# M061 register map
File version: 2.0.2.1
CPU: 
Registers are 32-bit, read-write, reset 0x0 unless marked. A register's access mark holds for its fields unless they carry their own. Offsets are from the block's base; [hi:lo] are bit positions; {n}, {i} and the like mark numbered series.

## TB0 — 16-bit Timer_Event Counter (TB)
Base 0x400C4000
Same registers: TB1 0x440C4100
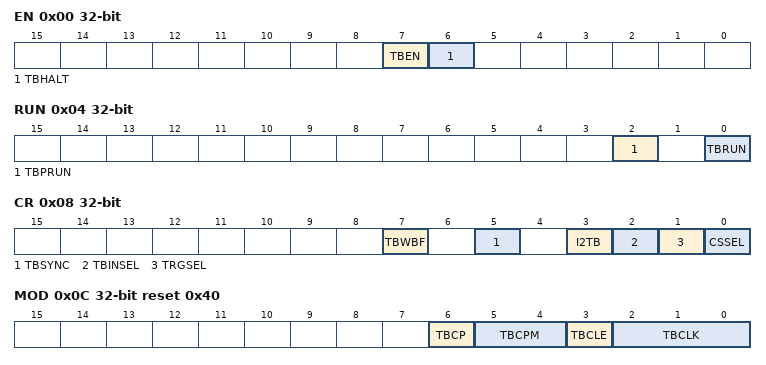
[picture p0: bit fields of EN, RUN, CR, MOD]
0x00 EN — TB Enable Register
  [7] TBEN, [6] TBHALT
0x04 RUN — TB RUN Register
  [2] TBPRUN, [0] TBRUN
0x08 CR — TB Control Register
  [7] TBWBF, [5] TBSYNC, [3] I2TB, [2] TBINSEL, [1] TRGSEL, [0] CSSEL
0x0C MOD reset 0x40 — TB Mode Register
  [6] TBCP wo, [5:4] TBCPM, [3] TBCLE, [2:0] TBCLK
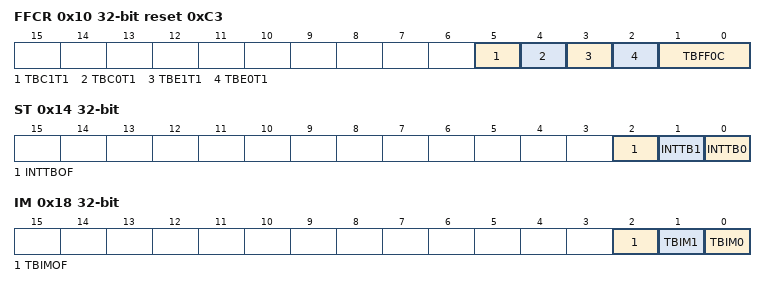
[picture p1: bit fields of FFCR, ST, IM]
0x10 FFCR reset 0xC3 — TB Flip-Flop Control Register
  [5] TBC1T1, [4] TBC0T1, [3] TBE1T1, [2] TBE0T1, [1:0] TBFF0C
0x14 ST ro — TB Status Register
  [2] INTTBOF, [1] INTTB1, [0] INTTB0
0x18 IM — TB Interrupt Mask Register
  [2] TBIMOF, [1] TBIM1, [0] TBIM0
0x1C UC ro — TB Read Capture Register
  [15:0] UC
0x20 RG0 — TB RG0 Timer Register
  [15:0] TBRG0
0x24 RG1 — TB RG1 Timer Register
  [15:0] TBRG1
0x28 CP0 ro (reset mask 0xFFFF0000) — TB CP0 Capture Register
  [15:0] TBCP0
0x2C CP1 ro (reset mask 0xFFFF0000) — TB CP1 Capture Register
  [15:0] TBCP1

## T16A0 — 16-bit TimerA
Base 0x4008D000
Same registers: T16A1 0x4008E000, T16A2 0x4008F000, T16A3 0x40090000, T16A4 0x40091000, T16A5 0x44092000, T16A6 0x44093000
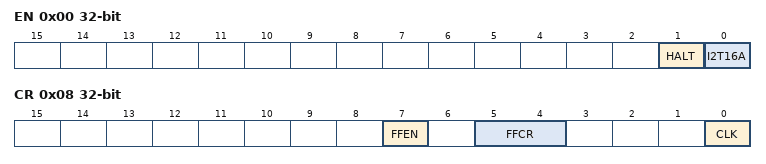
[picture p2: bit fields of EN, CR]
0x00 EN — Enable Register
  [1] HALT, [0] I2T16A
0x04 RUN
  [0] RUN
0x08 CR — Control Register
  [7] FFEN, [5:4] FFCR, [0] CLK
0x0C RG — Timer Register
  [15:0] RG
0x10 CP ro — Capture Register
  [15:0] CP

## WD0 — Watchdog Timer (WD)
Base 0x400F2000
Same registers: WD1 0x440F2100
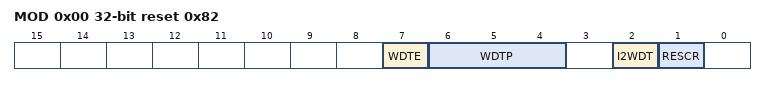
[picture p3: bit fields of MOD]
0x00 MOD reset 0x82 — WD Mode Register
  [7] WDTE, [6:4] WDTP, [2] I2WDT, [1] RESCR
0x04 CR wo (reset mask 0xFFFFFF00) — WD Control Register
  [7:0] WDCR

## SC0 — Serial Channel (SC)
Base 0x400E1000
Same registers: SC1 0x400E1100, SC2 0x400E1200, SC3 0x400E1300
0x00 EN — SC Enable Register
  [0] SIOE
0x04 BUF — SC Buffer Register
  [7:0] TB_RB
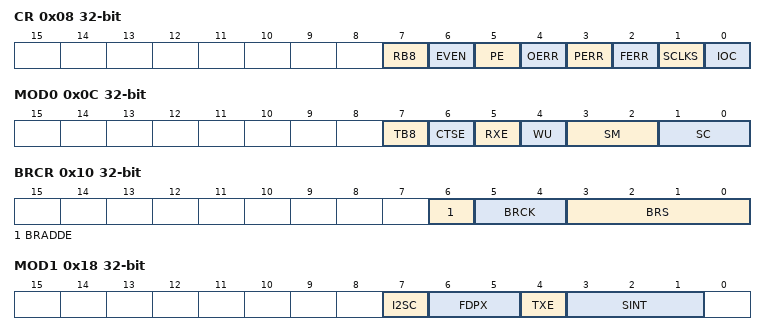
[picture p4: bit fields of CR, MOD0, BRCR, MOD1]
0x08 CR — SC Control Register
  [7] RB8 ro, [6] EVEN, [5] PE, [4] OERR ro, [3] PERR ro, [2] FERR ro, [1] SCLKS, [0] IOC
0x0C MOD0 — SC Mode Control Register 0
  [7] TB8, [6] CTSE, [5] RXE, [4] WU, [3:2] SM, [1:0] SC
0x10 BRCR — SC Baud Rate Generator Control Register
  [6] BRADDE, [5:4] BRCK, [3:0] BRS
0x14 BRADD — SC Baud Rate Generator Control Register 2
  [3:0] BRK
0x18 MOD1 — SC Mode Control Register 1
  [7] I2SC, [6:5] FDPX, [4] TXE, [3:1] SINT
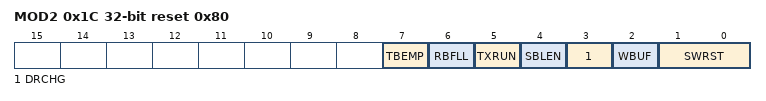
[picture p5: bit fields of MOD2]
0x1C MOD2 reset 0x80 — SC Mode Control Register 2
  [7] TBEMP ro, [6] RBFLL ro, [5] TXRUN ro, [4] SBLEN, [3] DRCHG, [2] WBUF, [1:0] SWRST

## SBI — Serial Bus Interface (SBI)
Base 0x400E0000
0x00 CR0 — SBI Control Register 0
  [7] SBIEN
0x04 CR1_A reset 0x3 — SBI Control Register 1 (I2C Mode)
  [7:5] BC, [4] ACK, [0] SWRMON ro, [2:0] SCK wo
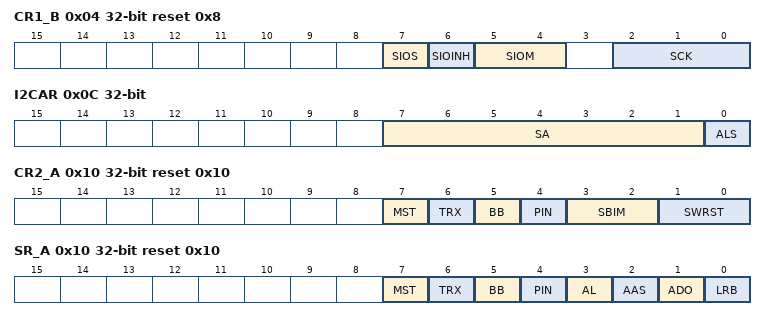
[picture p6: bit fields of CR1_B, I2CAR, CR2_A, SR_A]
0x04 CR1_B reset 0x8 (SBI_CR1 view) — SBI Control Register 1 (SIO Mode)
  [7] SIOS, [6] SIOINH, [5:4] SIOM, [2:0] SCK
0x08 DBR — SBI Data Buffer Register
  [7:0] DB
0x0C I2CAR — SBI I2C Bus Address Register
  [7:1] SA, [0] ALS
0x10 CR2_A wo reset 0x10 — SBI Control Register 2 (I2C Mode)
  [7] MST, [6] TRX, [5] BB, [4] PIN, [3:2] SBIM, [1:0] SWRST
0x10 CR2_B wo reset 0xF3 (SBI_CR2 view) — SBI Control Register 2 (SIO Mode)
  [3:2] SBIM
0x10 SR_A ro reset 0x10 — SBI Status Register (I2C Mode)
  [7] MST, [6] TRX, [5] BB, [4] PIN, [3] AL, [2] AAS, [1] ADO, [0] LRB
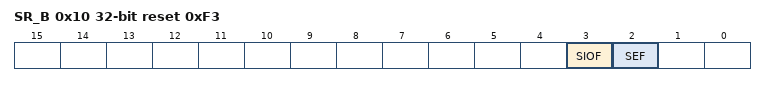
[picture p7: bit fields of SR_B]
0x10 SR_B ro reset 0xF3 (SBI_SR view) — SBI Status Register (SIO Mode)
  [3] SIOF, [2] SEF
0x14 BR0 reset 0xBE — SBI Baud Rate Register 0
  [6] I2SBI

## AD — Analog-to-Digital Converter (AD)
Base 0x400FC000
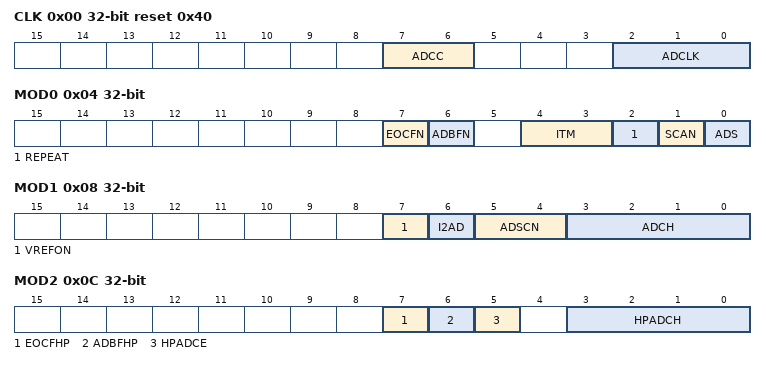
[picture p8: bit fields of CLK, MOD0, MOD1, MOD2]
0x00 CLK reset 0x40 — AD Conversion Clock Setting Register
  [7:6] ADCC, [2:0] ADCLK
0x04 MOD0 — AD Mode Control Register 0
  [7] EOCFN ro, [6] ADBFN ro, [4:3] ITM, [2] REPEAT, [1] SCAN, [0] ADS wo
0x08 MOD1 — AD Mode Control Register 1
  [7] VREFON, [6] I2AD, [5:4] ADSCN, [3:0] ADCH
0x0C MOD2 — AD Mode Control Register 2
  [7] EOCFHP ro, [6] ADBFHP ro, [5] HPADCE wo, [3:0] HPADCH
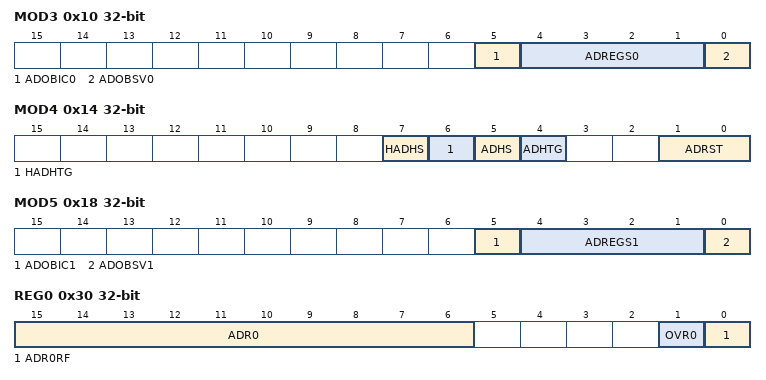
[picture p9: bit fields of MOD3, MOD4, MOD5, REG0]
0x10 MOD3 — AD Mode Control Register 3
  [5] ADOBIC0, [4:1] ADREGS0, [0] ADOBSV0
0x14 MOD4 — AD Mode Control Register 4
  [7] HADHS, [6] HADHTG, [5] ADHS, [4] ADHTG, [1:0] ADRST wo
0x18 MOD5 — AD Mode Control Register 5
  [5] ADOBIC1, [4:1] ADREGS1, [0] ADOBSV1
0x30 REG0 ro — AD Conversion Result Register 08
  [15:6] ADR0, [1] OVR0, [0] ADR0RF
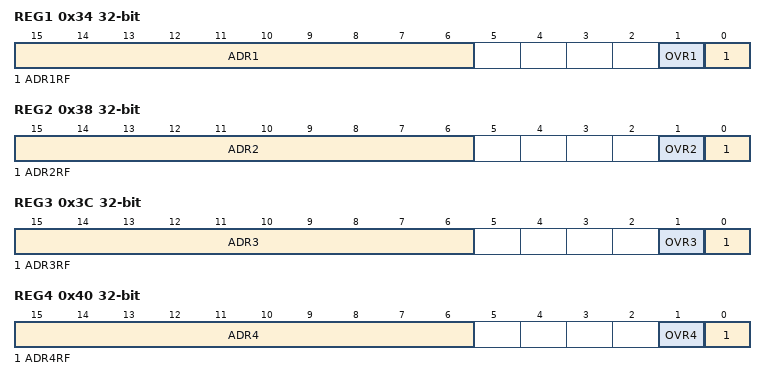
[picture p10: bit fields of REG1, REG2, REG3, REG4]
0x34 REG1 ro — AD Conversion Result Register 19
  [15:6] ADR1, [1] OVR1, [0] ADR1RF
0x38 REG2 ro — AD Conversion Result Register 2A
  [15:6] ADR2, [1] OVR2, [0] ADR2RF
0x3C REG3 ro — AD Conversion Result Register 3B
  [15:6] ADR3, [1] OVR3, [0] ADR3RF
0x40 REG4 ro — AD Conversion Result Register 4C
  [15:6] ADR4, [1] OVR4, [0] ADR4RF
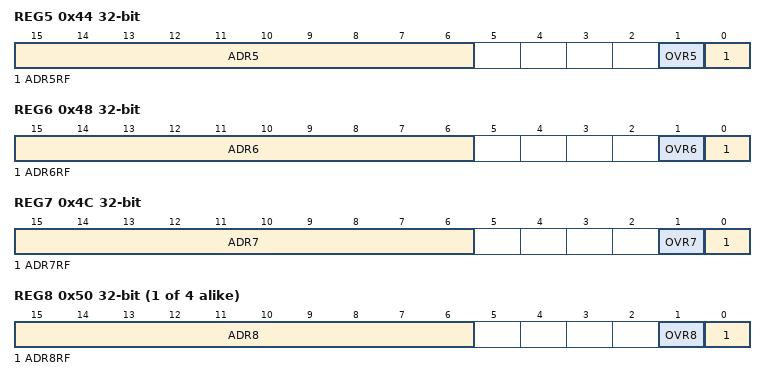
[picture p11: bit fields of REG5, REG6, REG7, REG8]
0x44 REG5 ro — AD Conversion Result Register 5D
  [15:6] ADR5, [1] OVR5, [0] ADR5RF
0x48 REG6 ro — AD Conversion Result Register 6E
  [15:6] ADR6, [1] OVR6, [0] ADR6RF
0x4C REG7 ro — AD Conversion Result Register 7F
  [15:6] ADR7, [1] OVR7, [0] ADR7RF
{0x30+4i} REG{i} ro (i=8..11) — AD Conversion Result Register {i}
  [15:6] ADR{i}, [1] OVR{i}, [0] ADR{i}RF
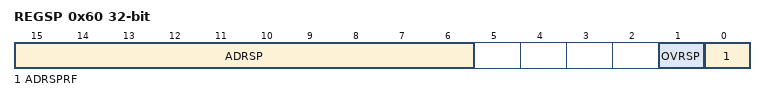
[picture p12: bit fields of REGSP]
0x60 REGSP ro — AD Conversion Result Register SP
  [15:6] ADRSP, [1] OVRSP, [0] ADRSPRF
0x64 CMP0 — AD Conversion Result Comparison Register 0
  [15:6] ADCOM0
0x68 CMP1 — AD Conversion Result Comparison Register 1
  [15:6] ADCOM1
